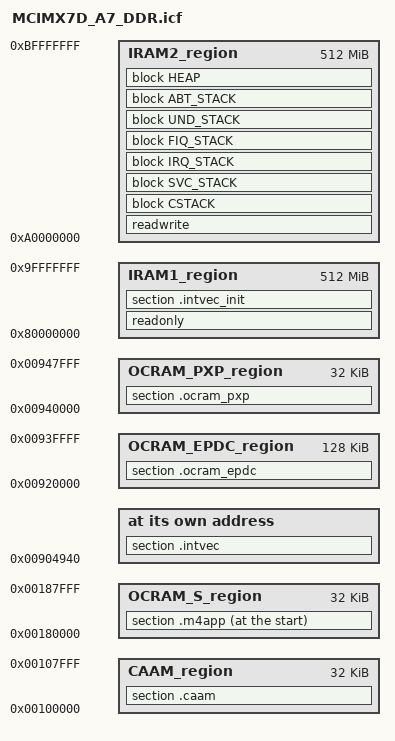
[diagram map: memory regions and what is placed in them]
/*###ICF### Section handled by ICF editor, don't touch! ****/
/*-Editor annotation file-*/
/* IcfEditorFile="$TOOLKIT_DIR$\config\ide\IcfEditor\a_v1_1.xml" */
/*-Specials-*/
define symbol __ICFEDIT_intvec_start__ = 0x00904940;
/*-Memory Regions-*/
define symbol __ICFEDIT_region_IROM1_start__ = 0x0;
define symbol __ICFEDIT_region_IROM1_end__   = 0x0;
define symbol __ICFEDIT_region_IROM2_start__ = 0x0;
define symbol __ICFEDIT_region_IROM2_end__   = 0x0;
define symbol __ICFEDIT_region_EROM1_start__ = 0x0;
define symbol __ICFEDIT_region_EROM1_end__   = 0x0;
define symbol __ICFEDIT_region_EROM2_start__ = 0x0;
define symbol __ICFEDIT_region_EROM2_end__   = 0x0;
define symbol __ICFEDIT_region_EROM3_start__ = 0x0;
define symbol __ICFEDIT_region_EROM3_end__   = 0x0;
define symbol __ICFEDIT_region_IRAM1_start__ = 0x80000000;
define symbol __ICFEDIT_region_IRAM1_end__   = 0x9FFFFFFF;
define symbol __ICFEDIT_region_IRAM2_start__ = 0xA0000000;
define symbol __ICFEDIT_region_IRAM2_end__   = 0xBFFFFFFF;
define symbol __ICFEDIT_region_ERAM1_start__ = 0x0;
define symbol __ICFEDIT_region_ERAM1_end__   = 0x0;
define symbol __ICFEDIT_region_ERAM2_start__ = 0x0;
define symbol __ICFEDIT_region_ERAM2_end__   = 0x0;
define symbol __ICFEDIT_region_ERAM3_start__ = 0x0;
define symbol __ICFEDIT_region_ERAM3_end__   = 0x0;
/*-Sizes-*/
define symbol __ICFEDIT_size_cstack__   = 0x2000;
define symbol __ICFEDIT_size_svcstack__ = 0x100;
define symbol __ICFEDIT_size_irqstack__ = 0x100;
define symbol __ICFEDIT_size_fiqstack__ = 0x100;
define symbol __ICFEDIT_size_undstack__ = 0x100;
define symbol __ICFEDIT_size_abtstack__ = 0x100;
define symbol __ICFEDIT_size_heap__     = 0x8000;
/**** End of ICF editor section. ###ICF###*/

/* OCRAM_PXP */
define symbol OCRAM_PXP_start__  = 0x00940000;
define symbol OCRAM_PXP_end__    = 0x00947FFF;

/* OCRAM_EPDC */
define symbol OCRAM_EPDC_start__ = 0x00920000;
define symbol OCRAM_EPDC_end__   = 0x0093FFFF;

/* Cortex-M4 - IROM1 region */
define symbol OCRAM_S_start__    = 0x00180000;
define symbol OCRAM_S_end__      = 0x00187FFF;

/* 32K Secure RAM */
define symbol CAAM_start__       = 0x00100000;
define symbol CAAM_end__         = 0x00107FFF;

define memory mem with size = 4G;
define region IROM_region   =   mem:[from __ICFEDIT_region_IROM1_start__ to __ICFEDIT_region_IROM1_end__]
                              | mem:[from __ICFEDIT_region_IROM2_start__ to __ICFEDIT_region_IROM2_end__];
define region EROM_region   =   mem:[from __ICFEDIT_region_EROM1_start__ to __ICFEDIT_region_EROM1_end__]
                              | mem:[from __ICFEDIT_region_EROM2_start__ to __ICFEDIT_region_EROM2_end__]
                              | mem:[from __ICFEDIT_region_EROM3_start__ to __ICFEDIT_region_EROM3_end__];
define region IRAM1_region  =   mem:[from __ICFEDIT_region_IRAM1_start__ to __ICFEDIT_region_IRAM1_end__];
define region IRAM2_region  =   mem:[from __ICFEDIT_region_IRAM2_start__ to __ICFEDIT_region_IRAM2_end__];
define region ERAM_region   =   mem:[from __ICFEDIT_region_ERAM1_start__ to __ICFEDIT_region_ERAM1_end__]
                              | mem:[from __ICFEDIT_region_ERAM2_start__ to __ICFEDIT_region_ERAM2_end__]
                              | mem:[from __ICFEDIT_region_ERAM3_start__ to __ICFEDIT_region_ERAM3_end__];

define region OCRAM_PXP_region  =   mem:[from OCRAM_PXP_start__  to OCRAM_PXP_end__ ];
define region OCRAM_EPDC_region =   mem:[from OCRAM_EPDC_start__ to OCRAM_EPDC_end__];
define region OCRAM_S_region    =   mem:[from OCRAM_S_start__    to OCRAM_S_end__];
define region CAAM_region       =   mem:[from CAAM_start__       to CAAM_end__];

define block CSTACK    with alignment = 8, size = __ICFEDIT_size_cstack__   { };
define block SVC_STACK with alignment = 8, size = __ICFEDIT_size_svcstack__ { };
define block IRQ_STACK with alignment = 8, size = __ICFEDIT_size_irqstack__ { };
define block FIQ_STACK with alignment = 8, size = __ICFEDIT_size_fiqstack__ { };
define block UND_STACK with alignment = 8, size = __ICFEDIT_size_undstack__ { };
define block ABT_STACK with alignment = 8, size = __ICFEDIT_size_abtstack__ { };
define block HEAP      with alignment = 8, size = __ICFEDIT_size_heap__     { };

do not initialize  { section .noinit };

initialize by copy { readwrite, section .intvec };

if (isdefinedsymbol(__USE_DLIB_PERTHREAD))
{
  // Required in a multi-threaded application
  initialize by copy with packing = none { section __DLIB_PERTHREAD };
}

initialize by copy with packing = auto { section .m4app };

place at address mem:__ICFEDIT_intvec_start__ { section .intvec };

place in IRAM1_region { readonly, section .intvec_init };
place in EROM_region  { readonly section application_specific_ro };
place in IRAM2_region { readwrite,
                        block CSTACK, block SVC_STACK, block IRQ_STACK, block FIQ_STACK,
                        block UND_STACK, block ABT_STACK, block HEAP };
place in ERAM_region  { readwrite section application_specific_rw };

place in OCRAM_PXP_region  { section .ocram_pxp  };
place in OCRAM_EPDC_region { section .ocram_epdc };
place in CAAM_region       { section .caam       };

place at start of OCRAM_S_region { section .m4app };
